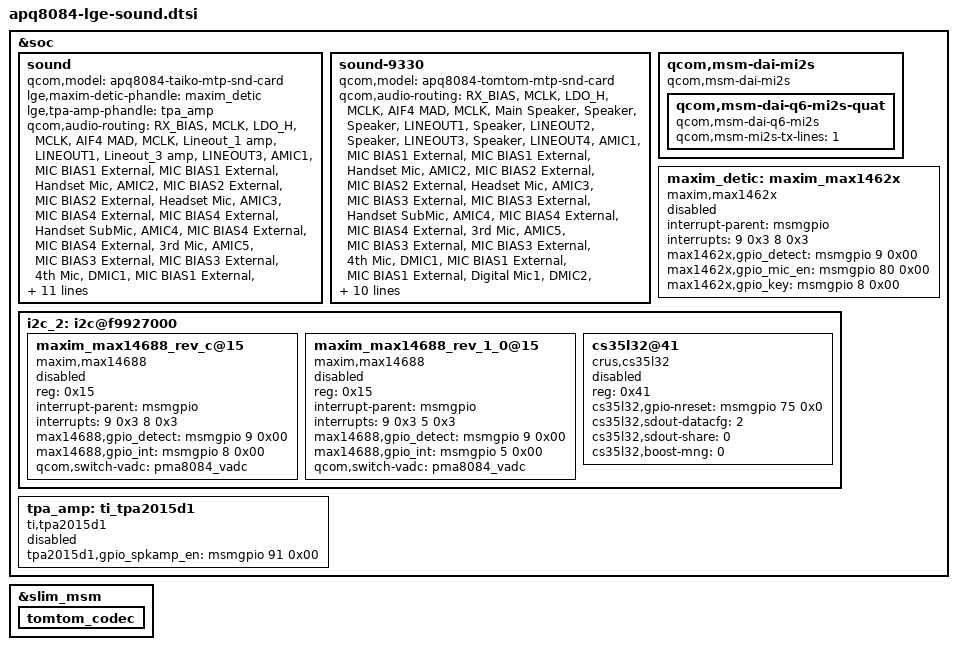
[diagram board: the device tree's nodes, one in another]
/* Copyright (c) 2012, Code Aurora Forum. All rights reserved.
 *
 * This program is free software; you can redistribute it and/or modify
 * it under the terms of the GNU General Public License version 2 and
 * only version 2 as published by the Free Software Foundation.
 *
 * This program is distributed in the hope that it will be useful,
 * but WITHOUT ANY WARRANTY; without even the implied warranty of
 * MERCHANTABILITY or FITNESS FOR A PARTICULAR PURPOSE.  See the
 * GNU General Public License for more details.
 */

&soc {
	sound {
		qcom,model = "apq8084-taiko-mtp-snd-card";

		lge,maxim-detic-phandle = <&maxim_detic>;
		lge,tpa-amp-phandle = <&tpa_amp>;

		qcom,audio-routing =
			"RX_BIAS", "MCLK",
			"LDO_H", "MCLK",
			"AIF4 MAD", "MCLK",

			"Lineout_1 amp", "LINEOUT1",
			"Lineout_3 amp", "LINEOUT3",

			"AMIC1", "MIC BIAS1 External",
			"MIC BIAS1 External", "Handset Mic",
			"AMIC2", "MIC BIAS2 External",
			"MIC BIAS2 External", "Headset Mic",
			"AMIC3", "MIC BIAS4 External",
			"MIC BIAS4 External", "Handset SubMic",
			"AMIC4", "MIC BIAS4 External",
			"MIC BIAS4 External", "3rd Mic",
			"AMIC5", "MIC BIAS3 External",
			"MIC BIAS3 External", "4th Mic",
			"DMIC1", "MIC BIAS1 External",
			"MIC BIAS1 External", "Digital Mic1",
			"DMIC2", "MIC BIAS1 External",
			"MIC BIAS1 External", "Digital Mic2",
			"DMIC3", "MIC BIAS3 External",
			"MIC BIAS3 External", "Digital Mic3",
			"DMIC4", "MIC BIAS3 External",
			"MIC BIAS3 External", "Digital Mic4",
			"DMIC5", "MIC BIAS4 External",
			"MIC BIAS4 External", "Digital Mic5",
			"DMIC6", "MIC BIAS4 External",
			"MIC BIAS4 External", "Digital Mic6";

		qcom,cdc-micbias2-headset-only;
		qcom,ext-mclk-gpio  = <&msmgpio 47 0>;
	};

	sound-9330 {
		qcom,model = "apq8084-tomtom-mtp-snd-card";

		qcom,audio-routing =
			"RX_BIAS", "MCLK",
			"LDO_H", "MCLK",
			"AIF4 MAD", "MCLK",
			"Main Speaker", "Speaker",
			"Speaker", "LINEOUT1",
			"Speaker", "LINEOUT2",
			"Speaker", "LINEOUT3",
			"Speaker", "LINEOUT4",

			"AMIC1", "MIC BIAS1 External",
			"MIC BIAS1 External", "Handset Mic",
			"AMIC2", "MIC BIAS2 External",
			"MIC BIAS2 External", "Headset Mic",
			"AMIC3", "MIC BIAS3 External",
			"MIC BIAS3 External", "Handset SubMic",
			"AMIC4", "MIC BIAS4 External",
			"MIC BIAS4 External", "3rd Mic",
			"AMIC5", "MIC BIAS3 External",
			"MIC BIAS3 External", "4th Mic",
			"DMIC1", "MIC BIAS1 External",
			"MIC BIAS1 External", "Digital Mic1",
			"DMIC2", "MIC BIAS1 External",
			"MIC BIAS1 External", "Digital Mic2",
			"DMIC3", "MIC BIAS3 External",
			"MIC BIAS3 External", "Digital Mic3",
			"DMIC4", "MIC BIAS3 External",
			"MIC BIAS3 External", "Digital Mic4",
			"DMIC5", "MIC BIAS4 External",
			"MIC BIAS4 External", "Digital Mic5",
			"DMIC6", "MIC BIAS4 External",
			"MIC BIAS4 External", "Digital Mic6";

		qcom,cdc-micbias2-headset-only;
		qcom,ext-mclk-gpio  = <&msmgpio 47 0>;
	};

	qcom,msm-dai-mi2s {
		compatible = "qcom,msm-dai-mi2s";
		qcom,msm-dai-q6-mi2s-quat {
			compatible = "qcom,msm-dai-q6-mi2s";
			qcom,msm-mi2s-tx-lines = <1>;
		};
	};

	maxim_detic:maxim_max1462x {
			compatible = "maxim,max1462x";
			status = "disable";
			interrupt-parent = <&msmgpio>;
			interrupts = <9 0x3 8 0x3>;
			max1462x,gpio_detect = <&msmgpio 9 0x00>;
			max1462x,gpio_mic_en = <&msmgpio 80 0x00>;
			max1462x,gpio_key = <&msmgpio 8 0x00>;
	};

	i2c_2: i2c@f9927000 {
		maxim_max14688_rev_c@15 {
			compatible = "maxim,max14688";
			status = "disable";
			reg = <0x15>;
			interrupt-parent = <&msmgpio>;
			interrupts = <9 0x3 8 0x3>;
			max14688,gpio_detect = <&msmgpio 9 0x00>;
			max14688,gpio_int = <&msmgpio 8 0x00>;
			qcom,switch-vadc = <&pma8084_vadc>;
		};
		maxim_max14688_rev_1_0@15 {
			compatible = "maxim,max14688";
			status = "disable";
			reg = <0x15>;
			interrupt-parent = <&msmgpio>;
			interrupts = <9 0x3 5 0x3>;
			max14688,gpio_detect = <&msmgpio 9 0x00>;
			max14688,gpio_int = <&msmgpio 5 0x00>;
			qcom,switch-vadc = <&pma8084_vadc>;
		};
		cs35l32@41 {
			status = "disable";
			reg = <0x41>;
			compatible = "crus,cs35l32";
			cs35l32,gpio-nreset = <&msmgpio 75 0x0>;
			cs35l32,sdout-datacfg = <2>;
			cs35l32,sdout-share = <0>;
			cs35l32,boost-mng = <0>;
		};
	};
	tpa_amp:ti_tpa2015d1 {
		compatible = "ti,tpa2015d1";
		status = "disable";
		tpa2015d1,gpio_spkamp_en = <&msmgpio 91 0x00>;
	};
};

&slim_msm {
	tomtom_codec {
		/delete-property/ qcom,cdc-micbias1-ext-cap;
		/delete-property/ qcom,cdc-micbias3-ext-cap;
	};
};
